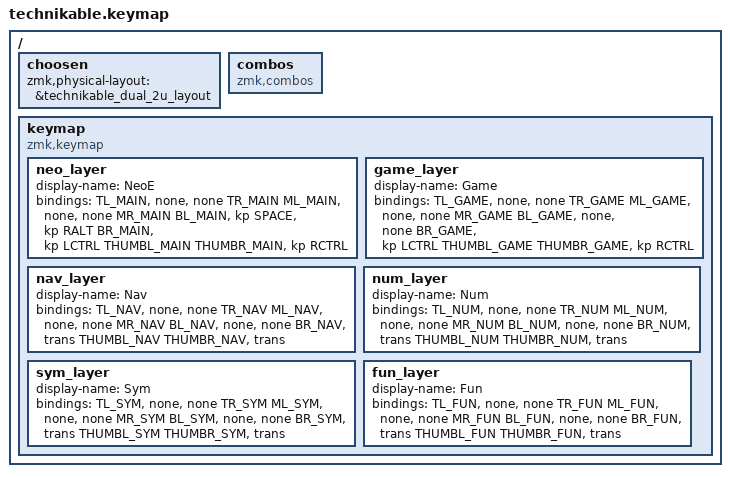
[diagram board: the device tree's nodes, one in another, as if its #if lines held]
/*
 * Copyright (c) 2022 Pete Johanson
 *
 * SPDX-License-Identifier: MIT
 */

#include <behaviors.dtsi>
/* #include <behaviors/num_word.dtsi> // requires auto-layer module */
#include <dt-bindings/zmk/keys.h>
#include <dt-bindings/zmk/bt.h>
#include <dt-bindings/zmk/outputs.h>

// #define TBLE_ORTHO   true
#define TBLE_MIT     true
//#define TBLE_DUAL_2U true

#include "zmk-helpers/helper.h"
#include "./fingers.dtsi"

#define COMBO_TIMEOUT 70
#define COMBO_LAYERS 1
#define STICKY_TIMEOUT 500

// LEFT SIDE
#define TLI 3 // TOP
#define TLM 2 // TOP
#define TLR 1 // TOP
#define TLP 0 // TOP
#define BLI 15 // BOTTOM
#define BLM 14 // BOTTOM
#define BLR 13 // BOTTOM
#define BLP 12 // BOTTOM
#define LOT 38 // O-THUMB
#define LIT 37 // I-THUMB

// RIGHT SIDE
#define TRI 8 // TOP
#define TRM 9 // TOP
#define TRR 10 // TOP
#define TRP 11 // TOP
#define BRI 20 // BOTTOM
#define BRM 21 // BOTTOM
#define BRR 22 // BOTTOM
#define BRP 23 // BOTTOM
#define ROT 40 // O-THUMB
#define RIT 41 // I-THUMB


#include "../../../merlinvn/config.dtsi"
#include "../../../merlinvn/macros.dtsi"
#include "../../../merlinvn/behaviors.dtsi"
#include "../../../merlinvn/combos.dtsi"
#include "../../../merlinvn/keymap.dtsi"

#define BT(n) BT_SEL n

/ {
/*     chosen { */
/*        zmk,matrix_transform = */
/* #ifdef TBLE_DUAL_2U */
/*                        &dual_2u_transform; */
/* #elif defined(TBLE_MIT) */
/*                        &mit_transform; */
/* #else */
/*                        &ortho_transform; */
/* #endif */
/*     }; */
    choosen {
      zmk,physical-layout =
#ifdef TBLE_DUAL_2U
                       &technikable_dual_2u_layout;
#elif defined(TBLE_MIT)
                       &technikable_mit_layout;
#else
                       &technikable_ortho_layout;
#endif
    };

    combos {
      compatible = "zmk,combos";
    };
    keymap {
        compatible = "zmk,keymap";


        neo_layer {
            display-name = "NeoE";
            bindings = <
                TL_MAIN      &none &none       TR_MAIN
                ML_MAIN      &none &none       MR_MAIN
                BL_MAIN      &kp SPACE &kp RALT       BR_MAIN
#ifdef TBLE_DUAL_2U
        &kp LCTRL  THUMBL_MAIN                                THUMBR_MAIN  &kp RCTRL
#elif defined(TBLE_MIT)
       &kp LGUI   THUMBL_MAIN           &kp LS(LC(LA(X)))     THUMBR_MAIN  &kp RGUI
#else
       &kp LCTRL  THUMBL_MAIN     &kp SPACE    &kp SPACE      THUMBR_MAIN  &kp RCTRL
#endif
            >;
        };

        game_layer {
            display-name = "Game";
            bindings = <
                TL_GAME &none &none TR_GAME
                ML_GAME &none &none MR_GAME
                BL_GAME &none &none BR_GAME
#ifdef TBLE_DUAL_2U
                &kp LCTRL THUMBL_GAME THUMBR_GAME &kp RCTRL
#elif defined(TBLE_MIT)
                &kp LCTRL THUMBL_GAME &none THUMBR_GAME &kp RCTRL
#else
                &kp LCTRL &kp LALT THUMBL_GAME &kp SPACE THUMBR_GAME &kp RALT &kp RCTRL
#endif
            >;
        };



        nav_layer {
            display-name = "Nav";
            bindings = <
                TL_NAV     &none  &none      TR_NAV
                ML_NAV     &none  &none      MR_NAV
                BL_NAV     &none  &none      BR_NAV
#ifdef TBLE_DUAL_2U
                      &trans     THUMBL_NAV                           THUMBR_NAV  &trans
#elif defined(TBLE_MIT)
                      &trans     THUMBL_NAV            &trans         THUMBR_NAV   &trans
#else
                      &trans     THUMBL_NAV      &trans       &trans  THUMBR_NAV   &trans
#endif
            >;
        };

        num_layer {
            display-name = "Num";
            bindings = <
                TL_NUM      &none  &none      TR_NUM
                ML_NUM      &none  &none      MR_NUM
                BL_NUM      &none  &none      BR_NUM
#ifdef TBLE_DUAL_2U
                     &trans     THUMBL_NUM                            THUMBR_NUM   &trans
#elif defined(TBLE_MIT)
                     &trans     THUMBL_NUM           &none            THUMBR_NUM   &trans
#else
                     &trans     THUMBL_NUM    &none         &none     THUMBR_NUM   &trans
#endif
            >;
        };

        sym_layer {
            display-name = "Sym";
            bindings = <
                TL_SYM     &none   &none      TR_SYM
                ML_SYM     &none   &none      MR_SYM
                BL_SYM     &none   &none      BR_SYM
#ifdef TBLE_DUAL_2U
                      &trans  THUMBL_SYM                            THUMBR_SYM  &trans
#elif defined(TBLE_MIT)
                      &trans  THUMBL_SYM           &trans           THUMBR_SYM  &trans
#else
                      &trans  THUMBL_SYM     &trans       &trans    THUMBR_SYM  &trans
#endif
            >;
        };

        fun_layer {
            display-name = "Fun";
            bindings = <
                TL_FUN    &none  &none     TR_FUN
                ML_FUN    &none  &none     MR_FUN
                BL_FUN    &none  &none     BR_FUN
#ifdef TBLE_DUAL_2U
                      &trans    THUMBL_FUN                               THUMBR_FUN  &trans
#elif defined(TBLE_MIT)
                      &trans    THUMBL_FUN              &trans           THUMBR_FUN  &trans
#else
                      &trans    THUMBL_FUN        &trans       &trans    THUMBR_FUN  &trans
#endif
            >;
        };



    };
};

